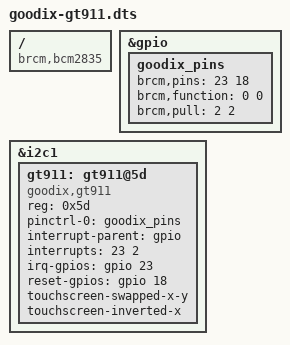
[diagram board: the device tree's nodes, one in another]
// Device tree overlay for I2C connected Goodix gt911 multiple touch controller
/dts-v1/;
/plugin/;

/ {
	compatible = "brcm,bcm2835";

	fragment@0 {
		target = <&gpio>;
		__overlay__ {
			goodix_pins: goodix_pins {
				brcm,pins = <23 18>; // interrupt and reset
				brcm,function = <0 0>; // in
				brcm,pull = <2 2>; // pull-up
			};
		};
	};

	fragment@1 {
		target = <&i2c1>;
		__overlay__ {
			#address-cells = <1>;
			#size-cells = <0>;
			status = "okay";

			gt911: gt911@5d {
				compatible = "goodix,gt911";
				reg = <0x5d>;
				pinctrl-names = "default";
				pinctrl-0 = <&goodix_pins>;
				interrupt-parent = <&gpio>;
				interrupts = <23 2>; // IRQ_TYPE_EDGE_FALLING
				irq-gpios = <&gpio 23 0>; // GPIO_ACTIVE_LOW
				reset-gpios = <&gpio 18 0>; // GPIO_ACTIVE_LOW
				touchscreen-swapped-x-y;
				touchscreen-inverted-x;
			};
		};
	};
};
